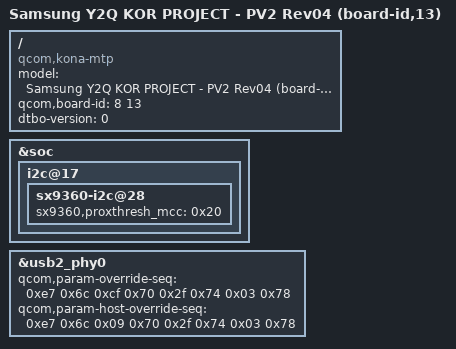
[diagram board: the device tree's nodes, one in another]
/* Copyright (c) 2019, The Linux Foundation. All rights reserved.
 *
 * This program is free software; you can redistribute it and/or modify
 * it under the terms of the GNU General Public License version 2 and
 * only version 2 as published by the Free Software Foundation.
 *
 * This program is distributed in the hope that it will be useful,
 * but WITHOUT ANY WARRANTY; without even the implied warranty of
 * MERCHANTABILITY or FITNESS FOR A PARTICULAR PURPOSE.  See the
 * GNU General Public License for more details.
 */

/dts-v1/;
/plugin/;

#include "../common/kona-sec-common.dtsi"
#include "kona-sec-y2q-r13.dtsi"

/ {
	model = "Samsung Y2Q KOR PROJECT - PV2 Rev04 (board-id,13)";
	compatible = "qcom,kona-mtp", "qcom,kona", "qcom,mtp";
	qcom,board-id = <8 13>;
	dtbo-version = <0>;
};

&soc {
	i2c@17 { /* SW I2C */
		status = "ok";
		sx9360-i2c@28 {
			sx9360,proxthresh_mcc = <0x20>; /* threshhold : 512 */
		};
	};
};

&usb2_phy0 {
	qcom,param-override-seq =
		<0xe7 0x6c
		 0xcf 0x70
		 0x2f 0x74
		 0x03 0x78>;
	qcom,param-host-override-seq =
		<0xe7 0x6c
		 0x09 0x70
		 0x2f 0x74
		 0x03 0x78>;
};
